# MCF5441x register map
Vendor: NXP; File version: 1.0
Registers are 32-bit, read-write, reset 0x0 unless marked. A register's access mark holds for its fields unless they carry their own. Offsets are from the block's base; [hi:lo] are bit positions; {n}, {i} and the like mark numbered series; 'fields as' and 'values as' point back to an identical list.

## SSI0
Base 0xFC0BC000
Same registers: SSI1 0xFC0C8000
0x00 TX0
  [31:0] SSI_TX
0x04 TX1
  [31:0] SSI_TX
0x08 RX0 ro
  [31:0] SSI_RX read-modifies
0x0C RX1 ro
  [31:0] SSI_RX read-modifies
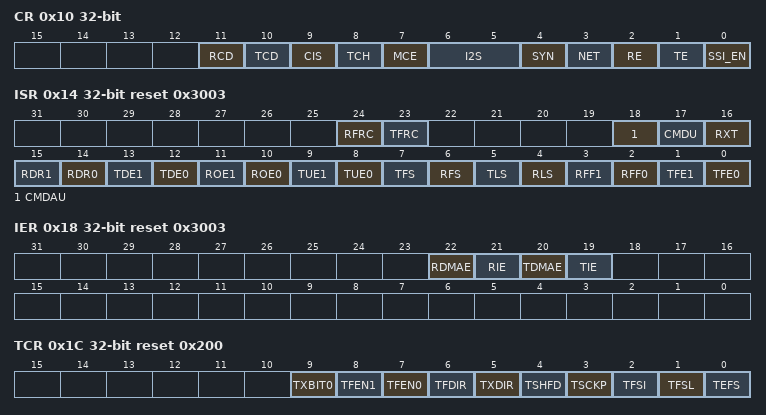
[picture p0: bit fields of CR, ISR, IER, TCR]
0x10 CR
  [11] RCD
  [10] TCD
  [9] CIS
    0=CLOCK_IDLE_STATE_IS_1; 1=CLOCK_IDLE_STATE_IS_0
  [8] TCH
    0=DISABLED; 1=ENABLED
  [7] MCE
  [6:5] I2S
    0=NORMAL_MODE; 1=I
  [4] SYN
    1=SYNCHRONOUS_MODE_SELECTED
  [3] NET
    0=NOT_SELECTED; 1=SELECTED
  [2] RE
    0=DISABLED; 1=ENABLED
  [1] TE
    0=DISABLED; 1=ENABLED
  [0] SSI_EN
    0=DISABLED; 1=ENABLED
0x14 ISR reset 0x3003
  [24] RFRC
  [23] TFRC
  [18] CMDAU
  [17] CMDU
  [16] RXT
  [15] RDR1
  [14] RDR0 ro
  [13] TDE1
  [12] TDE0
    0=AVAILABLE_FOR_TRA; 1=NEEDS_TO_BE_WRI
  [11] ROE1 write-1-clears
  [10] ROE0 write-1-clears
  [9] TUE1 write-1-clears
  [8] TUE0 write-1-clears
    0=NO_UNDERRUN_DETECTE; 1=TRANSMITTER_0_UNDERR
  [7] TFS
  [6] RFS ro
  [5] TLS ro
  [4] RLS ro
  [3] RFF1 ro
  [2] RFF0 ro
  [1] TFE1 ro
  [0] TFE0 ro
0x18 IER reset 0x3003
  [22] RDMAE, [21] RIE, [20] TDMAE, [19] TIE
0x1C TCR reset 0x200
  [9] TXBIT0
  [8] TFEN1
    0=DISABLED; 1=ENABLED
  [7] TFEN0
    0=DISABLED; 1=ENABLED
  [6] TFDIR
    0=IS_EXTERNAL; 1=GENERATED_INTERNALLY
  [5] TXDIR
    0=IS_EXTERNAL; 1=GENERATED_INTERNALLY
  [4] TSHFD
    0=MSB_FIRST; 1=LSB_FIRST
  [3] TSCKP
  [2] TFSI
  [1] TFSL
  [0] TEFS
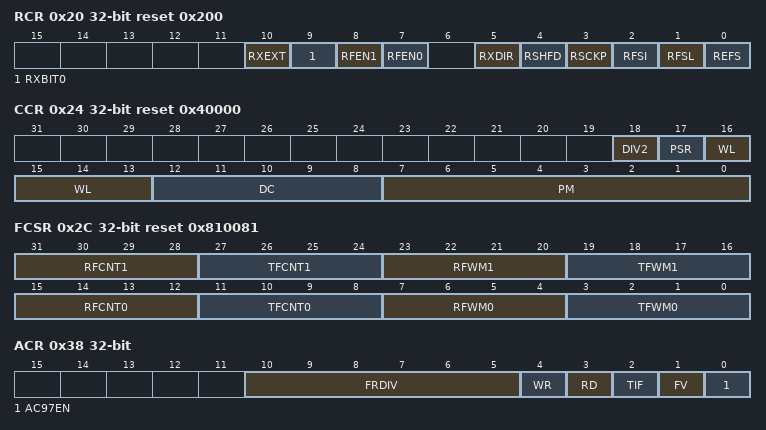
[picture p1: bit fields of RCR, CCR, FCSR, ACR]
0x20 RCR reset 0x200
  [10] RXEXT
    0=DISABLED; 1=ENABLED
  [9] RXBIT0
  [8] RFEN1
    0=DISABLED; 1=ENABLED
  [7] RFEN0
    0=DISABLED; 1=ENABLED
  [5] RXDIR
    0=DISABLED; 1=ENABLED
  [4] RSHFD
    0=MSB_FIRST; 1=LSB_FIRST
  [3] RSCKP
  [2] RFSI
  [1] RFSL
  [0] REFS
0x24 CCR reset 0x40000
  [18] DIV2, [17] PSR, [16:13] WL, [12:8] DC, [7:0] PM
0x2C FCSR reset 0x810081
  [31:28] RFCNT1 ro, [27:24] TFCNT1 ro, [23:20] RFWM1, [19:16] TFWM1, [15:12] RFCNT0 ro, [11:8] TFCNT0 ro, [7:4] RFWM0, [3:0] TFWM0
0x38 ACR
  [10:5] FRDIV
  [4] WR
  [3] RD
  [2] TIF
  [1] FV
    0=FIXED_MODE; 1=VARIABLE_MODE
  [0] AC97EN
    0=DISABLED; 1=ENABLED
0x3C ACADD
  [18:0] ACADD
0x40 ACDAT
  [19:0] ACDAT
0x44 ATAG
0x48 TMASK
0x4C RMASK
0x50 ACCSR ro
  [9:0] ACCSR
0x54 ACCEN wo
  [9:0] ACCEN
0x58 ACCDIS wo
  [9:0] ACCDIS

## UART0
Base 0xFC060000
Same registers: UART4 0xEC060000, UART5 0xEC064000, UART6 0xEC068000, UART7 0xEC06C000, UART8 0xEC070000, UART9 0xEC074000, UART1 0xFC064000, UART2 0xFC068000, UART3 0xFC06C000
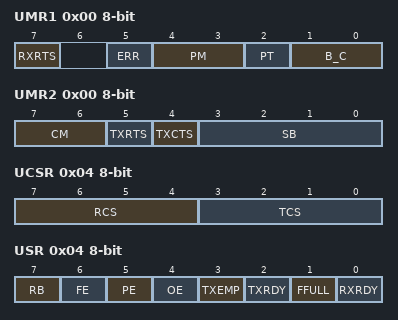
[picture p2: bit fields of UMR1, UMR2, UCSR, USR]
0x00 UMR1 8-bit
  [7] RXRTS, [5] ERR, [4:3] PM, [2] PT, [1:0] B_C
0x00 UMR2 8-bit
  [7:6] CM
    0=NORMAL; 1=AUTOMATIC_ECHO; 2=LOCAL_LOOPBACK; 3=REMOTE_LOOPBACK
  [5] TXRTS
  [4] TXCTS
  [3:0] SB
0x04 UCSR 8-bit wo reset not defined
  [7:4] RCS, [3:0] TCS
0x04 USR 8-bit ro
  [7] RB, [6] FE, [5] PE, [4] OE, [3] TXEMP, [2] TXRDY, [1] FFULL, [0] RXRDY
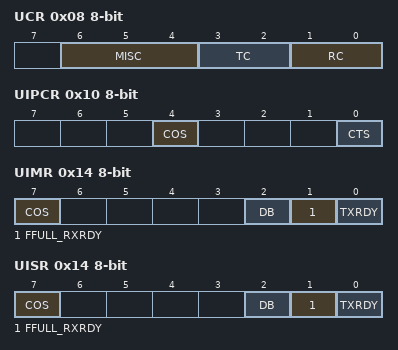
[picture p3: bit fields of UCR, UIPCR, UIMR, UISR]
0x08 UCR 8-bit wo
  [6:4] MISC, [3:2] TC, [1:0] RC
0x0C URB 8-bit ro reset 0xFF
  [7:0] RB read-modifies
0x0C UTB 8-bit wo
  [7:0] TB
0x10 UACR 8-bit wo
  [0] IEC
0x10 UIPCR 8-bit ro reset not defined
  [4] COS, [0] CTS
0x14 UIMR 8-bit wo
  [7] COS, [2] DB, [1] FFULL_RXRDY, [0] TXRDY
0x14 UISR 8-bit ro
  [7] COS, [2] DB, [1] FFULL_RXRDY, [0] TXRDY
0x18 UBG1 8-bit wo
0x1C UBG2 8-bit wo
0x34 UIP 8-bit ro reset 0xFF
  [0] CTS
0x38 UOP1 8-bit wo
  [0] RTS
    0=NO_EFFECT; 1=ASSERT
0x3C UOP0 8-bit wo
  [0] RTS
    0=NO_EFFECT; 1=NEGATE

## USBHOST
Base 0xFC0B4000
0x00 ID ro reset 0xE242FA05
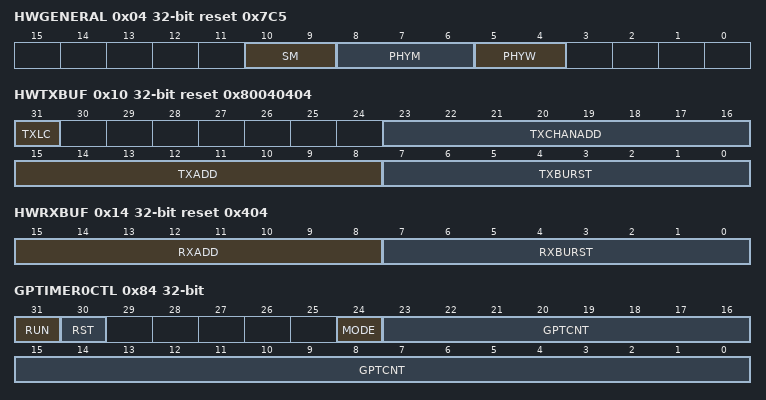
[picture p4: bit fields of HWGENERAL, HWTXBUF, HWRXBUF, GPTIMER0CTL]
0x04 HWGENERAL ro reset 0x7C5
  [10:9] SM, [8:6] PHYM, [5:4] PHYW
0x08 HWHOST ro reset 0x10020001
0x10 HWTXBUF ro reset 0x80040404
  [31] TXLC, [23:16] TXCHANADD, [15:8] TXADD, [7:0] TXBURST
0x14 HWRXBUF ro reset 0x404
  [15:8] RXADD, [7:0] RXBURST
0x80 GPTIMER0LD
  [23:0] GPTLD
0x84 GPTIMER0CTL
  [31] RUN
    0=STOP; 1=RUN
  [30] RST
    0=NO_ACTION; 1=LOAD_COUNTER_VALUE
  [24] MODE
    0=ONE_SHOT; 1=REPEAT
  [23:0] GPTCNT
0x88 GPTIMER1LD
  [23:0] GPTLD
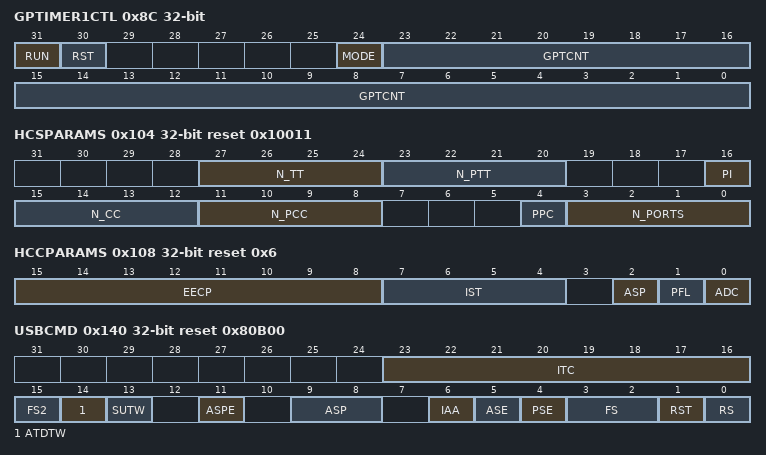
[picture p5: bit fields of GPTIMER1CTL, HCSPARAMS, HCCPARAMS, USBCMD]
0x8C GPTIMER1CTL
  fields as GPTIMER0CTL
0x100 HCIVERSION 16-bit ro reset 0x100
0x103 CAPLENGTH 8-bit ro reset 0x40
0x104 HCSPARAMS ro reset 0x10011
  [27:24] N_TT, [23:20] N_PTT, [16] PI, [15:12] N_CC, [11:8] N_PCC, [4] PPC, [3:0] N_PORTS
0x108 HCCPARAMS ro reset 0x6
  [15:8] EECP
  [7:4] IST
  [2] ASP
    0=NOT_SUPPORTED; 1=SUPPORTED
  [1] PFL
  [0] ADC
0x140 USBCMD reset 0x80B00
  [23:16] ITC
  [15] FS2
  [14] ATDTW
  [13] SUTW
  [11] ASPE
    0=DISABLED; 1=ENABLED
  [9:8] ASP
  [6] IAA
  [5] ASE
  [4] PSE
  [3:2] FS
  [1] RST
  [0] RS
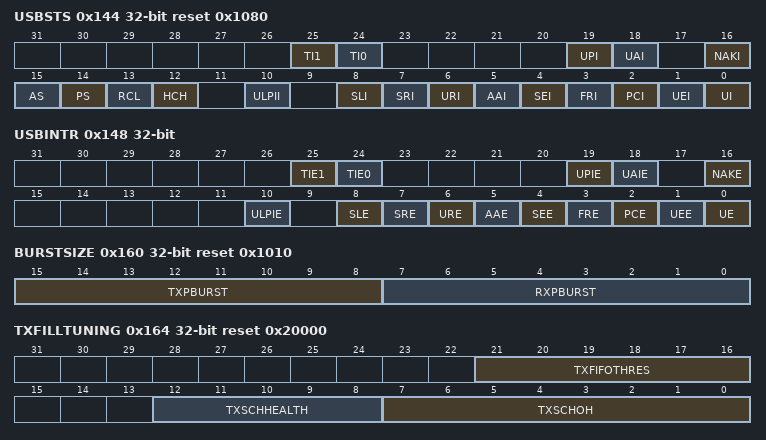
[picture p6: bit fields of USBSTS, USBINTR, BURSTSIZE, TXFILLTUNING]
0x144 USBSTS reset 0x1080
  [25] TI1 write-1-clears
    0=NO_INTERRUPT; 1=INTERRUPT_OCCURRED
  [24] TI0 write-1-clears
    0=NO_INTERRUPT; 1=INTERRUPT_OCCURRED
  [19] UPI
  [18] UAI
  [16] NAKI
  [15] AS
    0=DISABLED; 1=ENABLED
  [14] PS
    0=DISABLED; 1=ENABLED
  [13] RCL
    0=NON_EMPTY_ASYNCHRONOUS_SCHEDULE; 1=EMPTY_ASYNCHRONOUS_SCHEDULE
  [12] HCH
    0=RUNNING; 1=HALTED
  [10] ULPII
  [8] SLI write-1-clears
    0=ACTIVE; 1=SUSPENDED
  [7] SRI write-1-clears
  [6] URI write-1-clears
    0=NO_RESET_RECEIVED; 1=RESET_RECEIVED
  [5] AAI write-1-clears
    0=NO_ASYNC_ADVANCE_INTERRUPT; 1=ASYNC_ADVANCE_INTERRUPT
  [4] SEI write-1-clears
    0=NORMAL_OPERATION; 1=ERROR
  [3] FRI write-1-clears
  [2] PCI write-1-clears
  [1] UEI write-1-clears
    0=NO_ERROR; 1=ERROR_DETECTED
  [0] UI write-1-clears
0x148 USBINTR
  [25] TIE1
    0=DISABLED; 1=ENABLED
  [24] TIE0
    0=DISABLED; 1=ENABLED
  [19] UPIE
  [18] UAIE
  [16] NAKE
    0=DISABLED; 1=ENABLED
  [10] ULPIE
  [8] SLE
    0=DISABLED; 1=ENABLED
  [7] SRE
    0=DISABLED; 1=ENABLED
  [6] URE
    0=DISABLED; 1=ENABLED
  [5] AAE
    0=DISABLED; 1=ENABLED
  [4] SEE
    0=DISABLED; 1=ENABLED
  [3] FRE
    0=DISABLED; 1=ENABLED
  [2] PCE
    0=DISABLED; 1=ENABLED
  [1] UEE
    0=DISABLED; 1=ENABLED
  [0] UE
    0=DISABLED; 1=ENABLED
0x14C FRINDEX
  [13:0] FRINDEX
0x154 PERIODICLISTBASE
  [31:12] PERBASE
0x158 ASYNCLISTADDR
  [31:5] ASYBASE
0x15C TTCTRL
  [30:24] TTHA
0x160 BURSTSIZE reset 0x1010
  [15:8] TXPBURST, [7:0] RXPBURST
0x164 TXFILLTUNING reset 0x20000
  [21:16] TXFIFOTHRES, [12:8] TXSCHHEALTH, [7:0] TXSCHOH
0x180 CONFIGFLAG ro reset 0x1
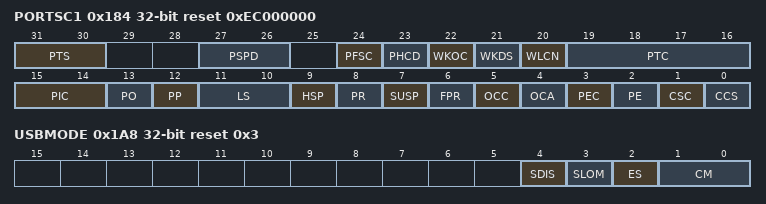
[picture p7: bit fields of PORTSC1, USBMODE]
0x184 PORTSC1 reset 0xEC000000
  [31:30] PTS
  [27:26] PSPD
    0=FULL_SPEED; 1=LOW_SPEED; 2=HIGH_SPEED; 3=UNDEFINED
  [24] PFSC
  [23] PHCD
  [22] WKOC
  [21] WKDS
  [20] WLCN
  [19:16] PTC
    0=NOT_ENABLED; 1=J_STATE; 2=K_STATE; 3=SEQ_NAK; 4=PACKET; 5=FORCE_ENABLE_HS; 6=FORCE_ENABLE_FS; 7=FORCE_ENABLE_LS
  [15:14] PIC
    0=OFF; 1=AMBER; 2=GREEN; 3=UNDEFINED
  [13] PO
  [12] PP
  [11:10] LS
    0=SE0; 1=J_STATE; 2=K_STATE; 3=UNDEFINED
  [9] HSP
    0=FS_OR_LS; 1=HS
  [8] PR
    0=NOT_IN_RESET; 1=IN_RESET
  [7] SUSP
  [6] FPR
  [5] OCC
    0=NO_OVER_CURRENT; 1=OVER_CURRENT_DETECT
  [4] OCA
  [3] PEC
    0=NO_CHANGE; 1=PORT_DISABLED
  [2] PE
  [1] CSC
    0=NO_CHANGE; 1=CONNECT_STATUS_HAS_CHANGED
  [0] CCS
0x1A8 USBMODE reset 0x3
  [4] SDIS
    0=INACTIVE; 1=ACTIVE
  [3] SLOM
  [2] ES
  [1:0] CM

## XBS
Base 0xFC004000
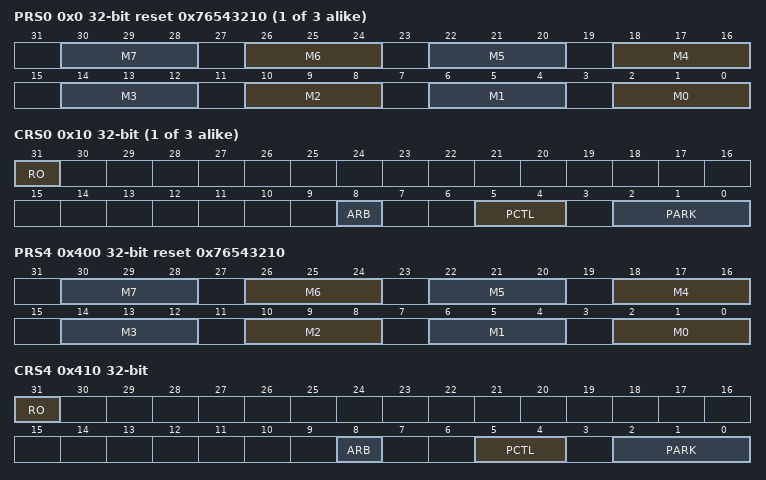
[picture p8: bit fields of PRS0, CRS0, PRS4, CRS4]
{0x0+0x100*i} PRS{i} reset 0x76543210 (i=0..2)
  [4n+2:4n] M{n} (n=0..7)
{0x10+0x100*i} CRS{i} (i=0..2)
  [31] RO, [8] ARB, [5:4] PCTL, [2:0] PARK
0x400 PRS4 reset 0x76543210
  [4n+2:4n] M{n} (n=0..7)
0x410 CRS4
  [31] RO, [8] ARB, [5:4] PCTL, [2:0] PARK
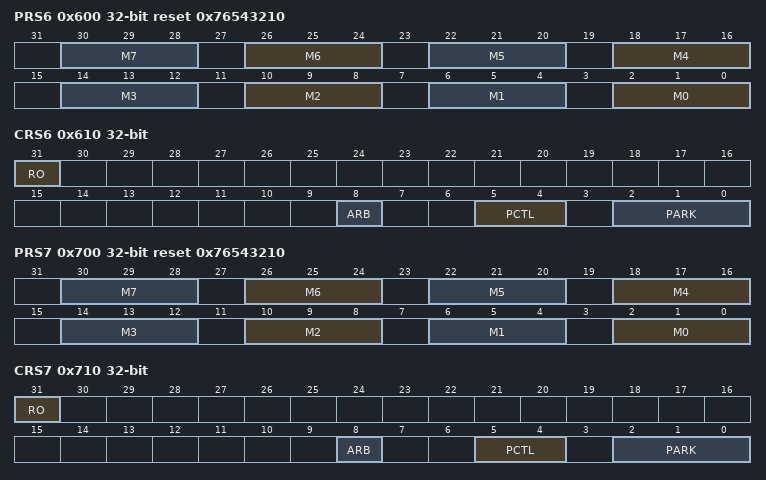
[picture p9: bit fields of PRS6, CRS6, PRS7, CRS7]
0x600 PRS6 reset 0x76543210
  [4n+2:4n] M{n} (n=0..7)
0x610 CRS6
  [31] RO, [8] ARB, [5:4] PCTL, [2:0] PARK
0x700 PRS7 reset 0x76543210
  [4n+2:4n] M{n} (n=0..7)
0x710 CRS7
  [31] RO, [8] ARB, [5:4] PCTL, [2:0] PARK
